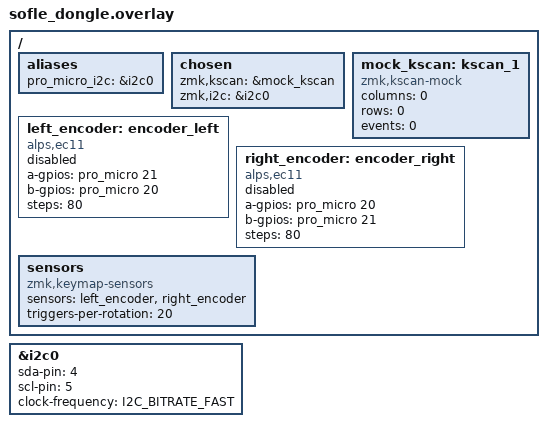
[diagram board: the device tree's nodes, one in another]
#include "sofle.dtsi"
/ { 
    aliases {
        pro_micro_i2c = &i2c0;
    };

    chosen {
        zmk,kscan = &mock_kscan;
        zmk,i2c = &i2c0;
    };

    mock_kscan: kscan_1 {
        compatible = "zmk,kscan-mock";
        columns = <0>;
        rows = <0>;
        events = <0>;
    };

    left_encoder: encoder_left {
        compatible = "alps,ec11";
        a-gpios = <&pro_micro 21 (GPIO_ACTIVE_HIGH | GPIO_PULL_UP)>;
        b-gpios = <&pro_micro 20 (GPIO_ACTIVE_HIGH | GPIO_PULL_UP)>;
        steps = <80>;
        status = "disabled";
    };

    right_encoder: encoder_right {
        compatible = "alps,ec11";
        a-gpios = <&pro_micro 20 (GPIO_ACTIVE_HIGH | GPIO_PULL_UP)>;
        b-gpios = <&pro_micro 21 (GPIO_ACTIVE_HIGH | GPIO_PULL_UP)>;
        steps = <80>;
        status = "disabled";
    };

    sensors: sensors {
        compatible = "zmk,keymap-sensors";
        sensors = <&left_encoder &right_encoder>;
        triggers-per-rotation = <20>;
    };
};

&i2c0 {
    status = "okay";
    sda-pin = <4>;  /* P0.04 for SDA */
    scl-pin = <5>;  /* P0.05 for SCL */
    clock-frequency = <I2C_BITRATE_FAST>;
};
